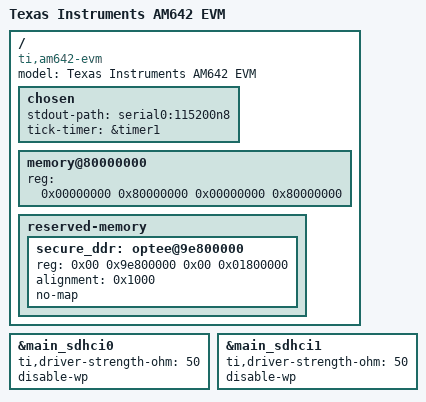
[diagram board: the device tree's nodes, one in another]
// SPDX-License-Identifier: GPL-2.0
/*
 * Copyright (C) 2020 Texas Instruments Incorporated - https://www.ti.com/
 */

/dts-v1/;

#include "k3-am642.dtsi"

/ {
	compatible =  "ti,am642-evm", "ti,am642";
	model = "Texas Instruments AM642 EVM";

	chosen {
		stdout-path = "serial0:115200n8";
		tick-timer = &timer1;
	};

	memory@80000000 {
		device_type = "memory";
		/* 2G RAM */
		reg = <0x00000000 0x80000000 0x00000000 0x80000000>;

	};

	reserved-memory {
		#address-cells = <2>;
		#size-cells = <2>;
		ranges;

		secure_ddr: optee@9e800000 {
			reg = <0x00 0x9e800000 0x00 0x01800000>; /* for OP-TEE */
			alignment = <0x1000>;
			no-map;
		};
	};
};

&main_sdhci0 {
	ti,driver-strength-ohm = <50>;
	disable-wp;
};

&main_sdhci1 {
	ti,driver-strength-ohm = <50>;
	disable-wp;
};
